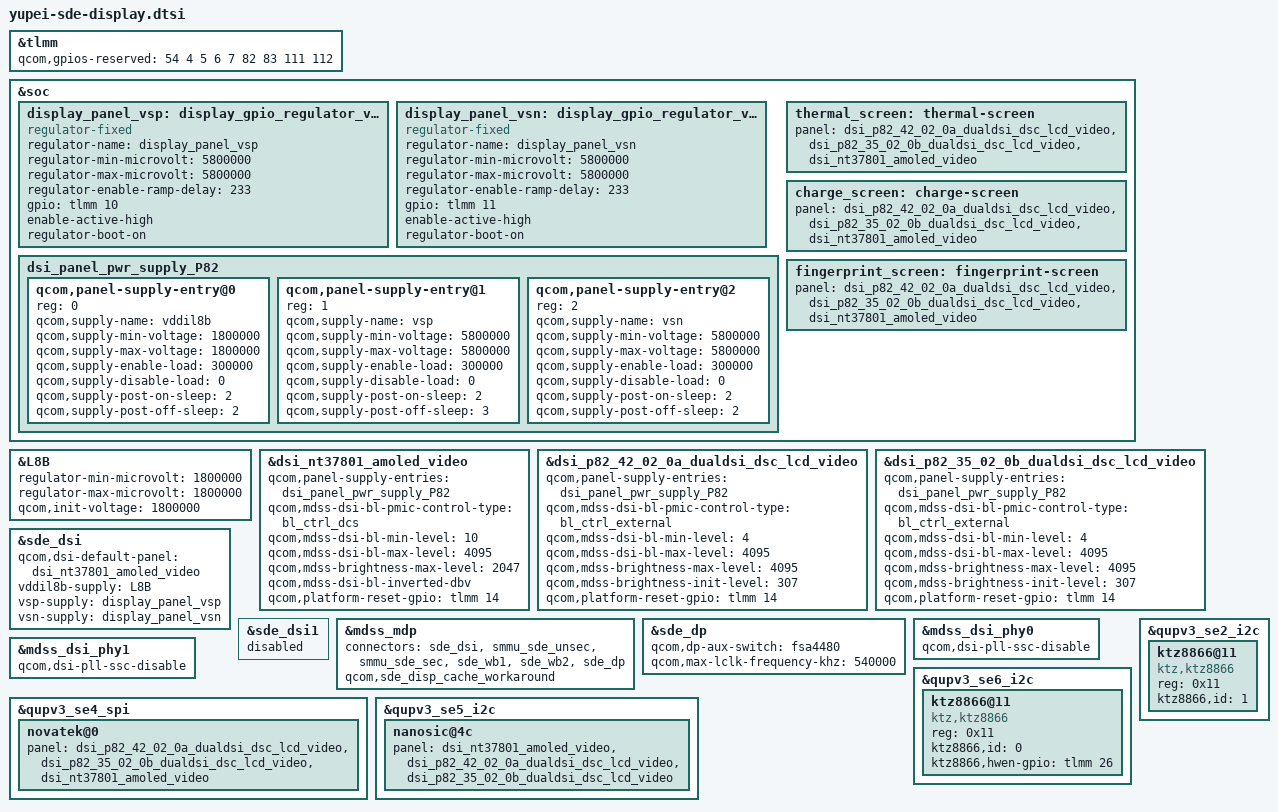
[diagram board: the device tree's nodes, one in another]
#include "tuna-sde-display.dtsi"
#include "dsi-panel-p82-42-02-0a-dualdsi-dsc-lcd-video.dtsi"
#include "dsi-panel-p82-35-02-0b-dualdsi-dsc-lcd-video.dtsi"
//#include "dsi-panel-nt37801-dsc-wqhd-plus-video.dtsi"

&tlmm {
	qcom,gpios-reserved = <54 4 5 6 7 82 83 111 112>;
};

&soc {
	display_panel_vsp: display_gpio_regulator_vsp {
		compatible = "regulator-fixed";
		regulator-name = "display_panel_vsp";
		regulator-min-microvolt = <5800000>;
		regulator-max-microvolt = <5800000>;
		regulator-enable-ramp-delay = <233>;
		gpio = <&tlmm 10 0>;
		enable-active-high;
		regulator-boot-on;
	};

	display_panel_vsn: display_gpio_regulator_vsn {
		compatible = "regulator-fixed";
		regulator-name = "display_panel_vsn";
		regulator-min-microvolt = <5800000>;
		regulator-max-microvolt = <5800000>;
		regulator-enable-ramp-delay = <233>;
		gpio = <&tlmm 11 0>;
		enable-active-high;
		regulator-boot-on;
	};

	dsi_panel_pwr_supply_P82: dsi_panel_pwr_supply_P82 {
		#address-cells = <1>;
		#size-cells = <0>;
		qcom,panel-supply-entry@0 {
			reg = <0>;
			qcom,supply-name = "vddil8b";
			qcom,supply-min-voltage = <1800000>;
			qcom,supply-max-voltage = <1800000>;
			qcom,supply-enable-load = <300000>;
			qcom,supply-disable-load = <0>;
			qcom,supply-post-on-sleep = <2>;
			qcom,supply-post-off-sleep = <2>;
		};

		qcom,panel-supply-entry@1 {
			reg = <1>;
			qcom,supply-name = "vsp";
			qcom,supply-min-voltage = <5800000>;
			qcom,supply-max-voltage = <5800000>;
			qcom,supply-enable-load = <300000>;
			qcom,supply-disable-load = <0>;
			qcom,supply-post-on-sleep = <2>;
			qcom,supply-post-off-sleep = <3>;
		};

		qcom,panel-supply-entry@2 {
			reg = <2>;
			qcom,supply-name = "vsn";
			qcom,supply-min-voltage = <5800000>;
			qcom,supply-max-voltage = <5800000>;
			qcom,supply-enable-load = <300000>;
			qcom,supply-disable-load = <0>;
			qcom,supply-post-on-sleep = <2>;
			qcom,supply-post-off-sleep = <2>;
		};
	};
};
&L8B {
	regulator-min-microvolt = <1800000>;
	regulator-max-microvolt = <1800000>;
	qcom,init-voltage = <1800000>;
};
&dsi_nt37801_amoled_video {
	qcom,panel-supply-entries = <&dsi_panel_pwr_supply_P82>;
	qcom,mdss-dsi-bl-pmic-control-type = "bl_ctrl_dcs";
	qcom,mdss-dsi-bl-min-level = <10>;
	qcom,mdss-dsi-bl-max-level = <4095>;
	qcom,mdss-brightness-max-level = <2047>;
	qcom,mdss-dsi-bl-inverted-dbv;
	qcom,platform-reset-gpio = <&tlmm 14 0>;
};

&dsi_p82_42_02_0a_dualdsi_dsc_lcd_video {
	qcom,panel-supply-entries = <&dsi_panel_pwr_supply_P82>;
	qcom,mdss-dsi-bl-pmic-control-type = "bl_ctrl_external";
	qcom,mdss-dsi-bl-min-level = <4>;
	qcom,mdss-dsi-bl-max-level = <4095>;
	qcom,mdss-brightness-max-level = <4095>;
	qcom,mdss-brightness-init-level = <307>;
	//qcom,mdss-dsi-bl-inverted-dbv;
	qcom,platform-reset-gpio = <&tlmm 14 0>;
};

&dsi_p82_35_02_0b_dualdsi_dsc_lcd_video {
	qcom,panel-supply-entries = <&dsi_panel_pwr_supply_P82>;
	qcom,mdss-dsi-bl-pmic-control-type = "bl_ctrl_external";
	qcom,mdss-dsi-bl-min-level = <4>;
	qcom,mdss-dsi-bl-max-level = <4095>;
	qcom,mdss-brightness-max-level = <4095>;
	qcom,mdss-brightness-init-level = <307>;
	//qcom,mdss-dsi-bl-inverted-dbv;
	qcom,platform-reset-gpio = <&tlmm 14 0>;
};

&sde_dsi {
	qcom,dsi-default-panel = <&dsi_nt37801_amoled_video>;
	vddil8b-supply = <&L8B>;
	vsp-supply = <&display_panel_vsp>;
	vsn-supply = <&display_panel_vsn>;
	//pinctrl-names = "panel_active", "panel_suspend";
	//pinctrl-0 = <&sde_dsi_active &sde_te_active>;
	//pinctrl-1 = <&sde_dsi_suspend &sde_te_suspend>;
};
&sde_dsi1 {
	status = "disabled";
};
&mdss_mdp {
	connectors = <&sde_dsi &smmu_sde_unsec &smmu_sde_sec &sde_wb1 &sde_wb2 &sde_dp>;
};

&mdss_mdp {
	qcom,sde_disp_cache_workaround;
};

&sde_dp {
	qcom,dp-aux-switch = <&fsa4480>;
	qcom,max-lclk-frequency-khz = <540000>;
	status = "ok";
};

/* close ssc */
&mdss_dsi_phy0 {
    qcom,dsi-pll-ssc-disable;
};
&mdss_dsi_phy1 {
    qcom,dsi-pll-ssc-disable;
};

&qupv3_se6_i2c {
	status = "ok";
	ktz8866@11 {
		compatible = "ktz,ktz8866";
		status = "ok";
		reg = <0x11>;
		ktz8866,id = <0>;
		ktz8866,hwen-gpio = <&tlmm 26 0x00>;
		//ktz8866,enp-gpio = <&tlmm 30 0x00>;
		//ktz8866,enn-gpio = <&tlmm 31 0x00>;
		//ktz8866,panelid-gpio = <&tlmm 10 0x00>;
		//ktz8866,backlight-HBM-enable;
	};
};

&qupv3_se2_i2c {
	status = "ok";
	ktz8866@11 {
		compatible = "ktz,ktz8866";
		status = "ok";
		reg = <0x11>;
		ktz8866,id = <1>;
	};
};


&qupv3_se4_spi {
	novatek@0 {
		panel = <&dsi_p82_42_02_0a_dualdsi_dsc_lcd_video
			&dsi_p82_35_02_0b_dualdsi_dsc_lcd_video
			&dsi_nt37801_amoled_video>;
	};
};

&qupv3_se5_i2c {
	nanosic@4c{
		panel = <&dsi_nt37801_amoled_video
				&dsi_p82_42_02_0a_dualdsi_dsc_lcd_video
				&dsi_p82_35_02_0b_dualdsi_dsc_lcd_video>;
	};
};

&soc {
	thermal_screen: thermal-screen {
		panel = <&dsi_p82_42_02_0a_dualdsi_dsc_lcd_video
		&dsi_p82_35_02_0b_dualdsi_dsc_lcd_video
		&dsi_nt37801_amoled_video>;
	};
	charge_screen: charge-screen {
		panel = <&dsi_p82_42_02_0a_dualdsi_dsc_lcd_video
		&dsi_p82_35_02_0b_dualdsi_dsc_lcd_video
		&dsi_nt37801_amoled_video>;
	};
	fingerprint_screen: fingerprint-screen {
		panel = <&dsi_p82_42_02_0a_dualdsi_dsc_lcd_video
		&dsi_p82_35_02_0b_dualdsi_dsc_lcd_video
		&dsi_nt37801_amoled_video>;
	};
};
